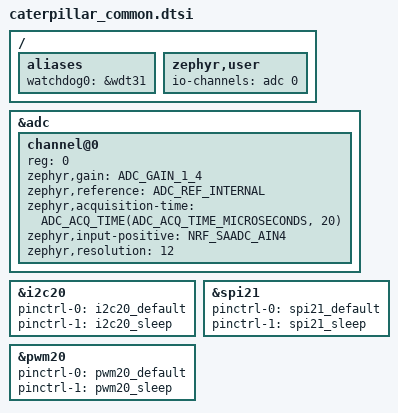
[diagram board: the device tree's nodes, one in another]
#include "caterpillar_nrf54l15-pinctrl.dtsi"
#include <zephyr/dt-bindings/adc/adc.h>
#include <zephyr/dt-bindings/adc/nrf-adc.h>

/ {
	aliases {
		watchdog0 = &wdt31;
	};

	zephyr,user {
		io-channels = <&adc 0>;
	};
};

/* VDC sense: motor rail → 100k/100k divider → AIN4 (P1.11), 100nF filter.
 * Gain 1/4 on the 0.9 V internal reference = 3.6 V full scale at the pin;
 * long acquisition time for the 50 kΩ divider source impedance.
 */
&adc {
	status = "okay";
	#address-cells = <1>;
	#size-cells = <0>;

	channel@0 {
		reg = <0>;
		zephyr,gain = "ADC_GAIN_1_4";
		zephyr,reference = "ADC_REF_INTERNAL";
		zephyr,acquisition-time = <ADC_ACQ_TIME(ADC_ACQ_TIME_MICROSECONDS, 20)>;
		zephyr,input-positive = <NRF_SAADC_AIN4>;
		zephyr,resolution = <12>;
	};
};

/* Digipot (MAX5419) only — the IMU moved to spi21 */
&i2c20 {
	status = "okay";
	pinctrl-0 = <&i2c20_default>;
	pinctrl-1 = <&i2c20_sleep>;
	pinctrl-names = "default", "sleep";
};

/* IMU (ASM330LHHTR).  CS is P1.09, driven as a GPIO by the IMU driver. */
&spi21 {
	status = "okay";
	pinctrl-0 = <&spi21_default>;
	pinctrl-1 = <&spi21_sleep>;
	pinctrl-names = "default", "sleep";
};

&pwm20 {
	status = "okay";
	pinctrl-0 = <&pwm20_default>;
	pinctrl-1 = <&pwm20_sleep>;
	pinctrl-names = "default", "sleep";
};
